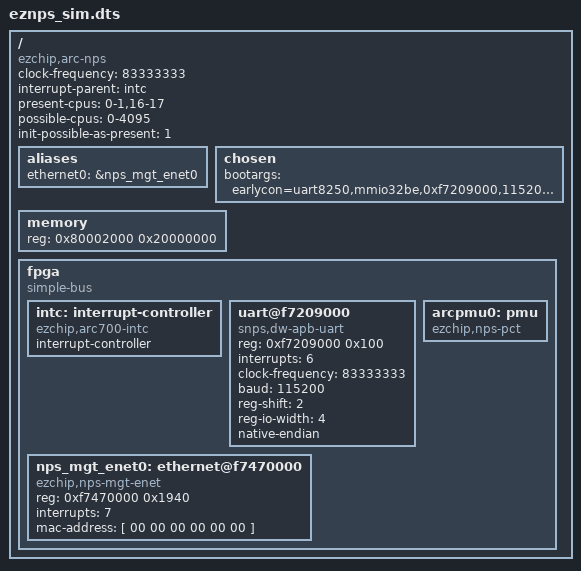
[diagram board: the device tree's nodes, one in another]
/*
* Copyright (c) 2016, Mellanox Technologies. All rights reserved.
*
* This software is available to you under a choice of one of two
* licenses.  You may choose to be licensed under the terms of the GNU
* General Public License (GPL) Version 2, available from the file
* COPYING in the main directory of this source tree, or the
* OpenIB.org BSD license below:
*
*     Redistribution and use in source and binary forms, with or
*     without modification, are permitted provided that the following
*     conditions are met:
*
*      - Redistributions of source code must retain the above
*        copyright notice, this list of conditions and the following
*        disclaimer.
*
*      - Redistributions in binary form must reproduce the above
*        copyright notice, this list of conditions and the following
*        disclaimer in the documentation and/or other materials
*        provided with the distribution.
*
* THE SOFTWARE IS PROVIDED "AS IS", WITHOUT WARRANTY OF ANY KIND,
* EXPRESS OR IMPLIED, INCLUDING BUT NOT LIMITED TO THE WARRANTIES OF
* MERCHANTABILITY, FITNESS FOR A PARTICULAR PURPOSE AND
* NONINFRINGEMENT. IN NO EVENT SHALL THE AUTHORS OR COPYRIGHT HOLDERS
* BE LIABLE FOR ANY CLAIM, DAMAGES OR OTHER LIABILITY, WHETHER IN AN
* ACTION OF CONTRACT, TORT OR OTHERWISE, ARISING FROM, OUT OF OR IN
* CONNECTION WITH THE SOFTWARE OR THE USE OR OTHER DEALINGS IN THE
* SOFTWARE.
*/
/dts-v1/;

/include/ "skeleton.dtsi"

/ {
	compatible = "ezchip,arc-nps";
	clock-frequency = <83333333>;	/* 83.333333 MHZ */
	#address-cells = <1>;
	#size-cells = <1>;
	interrupt-parent = <&intc>;
	present-cpus = "0-1,16-17";
	possible-cpus = "0-4095";
	init-possible-as-present = <1>;

	aliases {
		ethernet0 = &nps_mgt_enet0;
	};
	
	chosen {
		bootargs = "earlycon=uart8250,mmio32be,0xf7209000,115200n8 console=ttyS0,115200n8 rcupdate.rcu_cpu_stall_suppress=1";
	};

	memory {
		device_type = "memory";
		reg = <0x80002000 0x20000000>;    /* 512M */
	};

	fpga {
		compatible = "simple-bus";
		#address-cells = <1>;
		#size-cells = <1>;

		/* child and parent address space 1:1 mapped */
		ranges;

		intc: interrupt-controller {
			compatible = "ezchip,arc700-intc";
			interrupt-controller;
			#interrupt-cells = <1>;
		};

		uart@f7209000 {
			compatible = "snps,dw-apb-uart";
			device_type = "serial";
			reg = <0xf7209000 0x100>;
			interrupts = <6>;
			clock-frequency = <83333333>;
			baud = <115200>;
			reg-shift = <2>;
			reg-io-width = <4>;
			native-endian;
		};

		nps_mgt_enet0: ethernet@f7470000 {
			compatible = "ezchip,nps-mgt-enet";
			reg = <0xf7470000 0x1940>;
			interrupts = <7>;
			/* Filled in by U-Boot */
			mac-address = [ 00 00 00 00 00 00 ];
		};

		arcpmu0: pmu {
			compatible = "ezchip,nps-pct";
		};
	};
};
